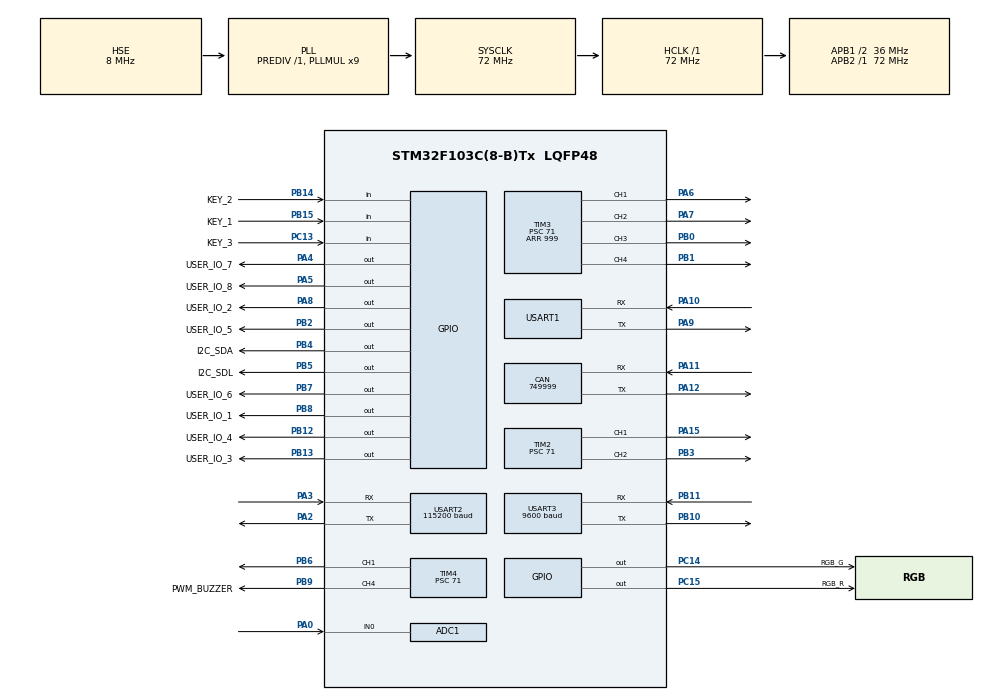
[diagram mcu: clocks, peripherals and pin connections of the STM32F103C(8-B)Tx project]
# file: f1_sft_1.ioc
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ADC1.Channel-4\#ChannelRegularConversion=ADC_CHANNEL_0
ADC1.NbrOfConversionFlag=1
ADC1.Rank-4\#ChannelRegularConversion=1
ADC1.SamplingTime-4\#ChannelRegularConversion=ADC_SAMPLETIME_1CYCLE_5
ADC1.master=1
CAN.CalculateBaudRate=749999
CAN.CalculateTimeBit=1333
CAN.CalculateTimeQuantum=444.44444444444446
Dma.Request0=USART1_RX
Dma.Request1=USART2_RX
Dma.Request2=USART1_TX
Dma.Request3=USART2_TX
Dma.USART1_RX.0.Direction=DMA_PERIPH_TO_MEMORY
Dma.USART1_RX.0.Instance=DMA1_Channel5
Dma.USART1_RX.0.MemDataAlignment=DMA_MDATAALIGN_BYTE
Dma.USART1_RX.0.MemInc=DMA_MINC_ENABLE
Dma.USART1_RX.0.Mode=DMA_CIRCULAR
Dma.USART1_RX.0.PeriphDataAlignment=DMA_PDATAALIGN_BYTE
Dma.USART1_RX.0.PeriphInc=DMA_PINC_DISABLE
Dma.USART1_RX.0.Priority=DMA_PRIORITY_LOW
Dma.USART1_TX.2.Direction=DMA_MEMORY_TO_PERIPH
Dma.USART1_TX.2.Instance=DMA1_Channel4
Dma.USART1_TX.2.MemDataAlignment=DMA_MDATAALIGN_BYTE
Dma.USART1_TX.2.MemInc=DMA_MINC_ENABLE
Dma.USART1_TX.2.Mode=DMA_NORMAL
Dma.USART1_TX.2.PeriphDataAlignment=DMA_PDATAALIGN_BYTE
Dma.USART1_TX.2.PeriphInc=DMA_PINC_DISABLE
Dma.USART1_TX.2.Priority=DMA_PRIORITY_LOW
Dma.USART2_RX.1.Direction=DMA_PERIPH_TO_MEMORY
Dma.USART2_RX.1.Instance=DMA1_Channel6
Dma.USART2_RX.1.MemDataAlignment=DMA_MDATAALIGN_BYTE
Dma.USART2_RX.1.MemInc=DMA_MINC_ENABLE
Dma.USART2_RX.1.Mode=DMA_CIRCULAR
Dma.USART2_RX.1.PeriphDataAlignment=DMA_PDATAALIGN_BYTE
Dma.USART2_RX.1.PeriphInc=DMA_PINC_DISABLE
Dma.USART2_RX.1.Priority=DMA_PRIORITY_LOW
Dma.USART2_TX.3.Direction=DMA_MEMORY_TO_PERIPH
Dma.USART2_TX.3.Instance=DMA1_Channel7
Dma.USART2_TX.3.MemDataAlignment=DMA_MDATAALIGN_BYTE
Dma.USART2_TX.3.MemInc=DMA_MINC_ENABLE
Dma.USART2_TX.3.Mode=DMA_NORMAL
Dma.USART2_TX.3.PeriphDataAlignment=DMA_PDATAALIGN_BYTE
Dma.USART2_TX.3.PeriphInc=DMA_PINC_DISABLE
Dma.USART2_TX.3.Priority=DMA_PRIORITY_LOW
FREERTOS.Tasks01=defaultTask,24,512,systemTaskUpdata,As weak,NULL,Dynamic,NULL,NULL;userTask_1,24,512,user1TaskUpdata,As weak,NULL,Dynamic,NULL,NULL;userTask_2,24,512,user2TaskUpdata,As weak,NULL,Dynamic,NULL,NULL
FREERTOS.configTOTAL_HEAP_SIZE=10240
Mcu.Family=STM32F1
Mcu.Name=STM32F103C(8-B)Tx
Mcu.Package=LQFP48
NVIC.DMA1_Channel4_IRQn=true\:5\:0\:false\:false\:true\:true\:false\:true\:true
NVIC.DMA1_Channel5_IRQn=true\:5\:0\:false\:false\:true\:true\:false\:true\:true
NVIC.DMA1_Channel6_IRQn=true\:5\:0\:false\:false\:true\:true\:false\:true\:true
NVIC.DMA1_Channel7_IRQn=true\:5\:0\:false\:false\:true\:true\:false\:true\:true
NVIC.PriorityGroup=NVIC_PRIORITYGROUP_4
NVIC.TIM1_UP_IRQn=true\:15\:0\:false\:false\:true\:false\:false\:true\:true
NVIC.TimeBase=TIM1_UP_IRQn
NVIC.TimeBaseIP=TIM1
NVIC.USART1_IRQn=true\:5\:0\:false\:false\:true\:true\:true\:true\:true
NVIC.USART2_IRQn=true\:5\:0\:false\:false\:true\:true\:true\:true\:true
NVIC.USART3_IRQn=true\:5\:0\:false\:false\:true\:true\:true\:true\:true
PA0-WKUP.Signal=ADCx_IN0
PA10.Mode=Asynchronous
PA10.Signal=USART1_RX
PA11.Mode=CAN_Activate
PA11.Signal=CAN_RX
PA12.Mode=CAN_Activate
PA12.Signal=CAN_TX
PA13.Mode=Serial_Wire
PA13.Signal=SYS_JTMS-SWDIO
PA14.Mode=Serial_Wire
PA14.Signal=SYS_JTCK-SWCLK
PA15.Signal=S_TIM2_CH1_ETR
PA2.Mode=Asynchronous
PA2.Signal=USART2_TX
PA3.Mode=Asynchronous
PA3.Signal=USART2_RX
PA4.GPIO_Label=USER_IO_7
PA4.GPIO_PuPd=GPIO_PULLUP
PA4.Signal=GPIO_Output
PA5.GPIO_Label=USER_IO_8
PA5.GPIO_PuPd=GPIO_PULLUP
PA5.Signal=GPIO_Output
PA6.Signal=S_TIM3_CH1
PA7.Signal=S_TIM3_CH2
PA8.GPIO_Label=USER_IO_2
PA8.GPIO_PuPd=GPIO_PULLUP
PA8.Signal=GPIO_Output
PA9.Mode=Asynchronous
PA9.Signal=USART1_TX
PB0.Signal=S_TIM3_CH3
PB1.Signal=S_TIM3_CH4
PB10.Mode=Asynchronous
PB10.Signal=USART3_TX
PB11.Mode=Asynchronous
PB11.Signal=USART3_RX
PB12.GPIO_Label=USER_IO_4
PB12.GPIO_PuPd=GPIO_PULLUP
PB12.Signal=GPIO_Output
PB13.GPIO_Label=USER_IO_3
PB13.GPIO_PuPd=GPIO_PULLUP
PB13.Signal=GPIO_Output
PB14.GPIO_Label=KEY_2
PB14.GPIO_PuPd=GPIO_PULLUP
PB14.Signal=GPIO_Input
PB15.GPIO_Label=KEY_1
PB15.GPIO_PuPd=GPIO_PULLUP
PB15.Signal=GPIO_Input
PB2.GPIO_Label=USER_IO_5
PB2.GPIO_PuPd=GPIO_PULLUP
PB2.Signal=GPIO_Output
PB3.Signal=S_TIM2_CH2
PB4.GPIO_Label=I2C_SDA
PB4.GPIO_ModeDefaultOutputPP=GPIO_MODE_OUTPUT_OD
PB4.GPIO_PuPd=GPIO_PULLUP
PB4.Signal=GPIO_Output
PB5.GPIO_Label=I2C_SDL
PB5.GPIO_PuPd=GPIO_PULLUP
PB5.Signal=GPIO_Output
PB6.Signal=S_TIM4_CH1
PB7.GPIO_Label=USER_IO_6
PB7.GPIO_PuPd=GPIO_PULLUP
PB7.Signal=GPIO_Output
PB8.GPIO_Label=USER_IO_1
PB8.GPIO_PuPd=GPIO_PULLUP
PB8.Signal=GPIO_Output
PB9.GPIO_Label=PWM_BUZZER
PB9.Signal=S_TIM4_CH4
PC13-TAMPER-RTC.GPIO_Label=KEY_3
PC13-TAMPER-RTC.GPIO_PuPd=GPIO_PULLUP
PC13-TAMPER-RTC.Signal=GPIO_Input
PC14-OSC32_IN.GPIO_Label=RGB_G
PC14-OSC32_IN.GPIO_PuPd=GPIO_PULLDOWN
PC14-OSC32_IN.Signal=GPIO_Output
PC15-OSC32_OUT.GPIO_Label=RGB_R
PC15-OSC32_OUT.GPIO_PuPd=GPIO_PULLDOWN
PC15-OSC32_OUT.Signal=GPIO_Output
PD0-OSC_IN.Mode=HSE-External-Oscillator
PD0-OSC_IN.Signal=RCC_OSC_IN
PD1-OSC_OUT.Mode=HSE-External-Oscillator
PD1-OSC_OUT.Signal=RCC_OSC_OUT
ProjectManager.HeapSize=0x200
ProjectManager.StackSize=0x400
ProjectManager.TargetToolchain=MDK-ARM V5
RCC.ADCPresc=RCC_ADCPCLK2_DIV6
RCC.AHBFreq_Value=72000000
RCC.APB1CLKDivider=RCC_HCLK_DIV2
RCC.APB1Freq_Value=36000000
RCC.APB1TimFreq_Value=72000000
RCC.APB2Freq_Value=72000000
RCC.APB2TimFreq_Value=72000000
RCC.HCLKFreq_Value=72000000
RCC.PLLMUL=RCC_PLL_MUL9
RCC.PLLSourceVirtual=RCC_PLLSOURCE_HSE
RCC.SYSCLKFreq_VALUE=72000000
RCC.SYSCLKSource=RCC_SYSCLKSOURCE_PLLCLK
RCC.USBFreq_Value=72000000
SH.ADCx_IN0.0=ADC1_IN0,IN0
SH.S_TIM2_CH1_ETR.0=TIM2_CH1,PWM Generation1 CH1
SH.S_TIM2_CH2.0=TIM2_CH2,PWM Generation2 CH2
SH.S_TIM3_CH1.0=TIM3_CH1,PWM Generation1 CH1
SH.S_TIM3_CH2.0=TIM3_CH2,PWM Generation2 CH2
SH.S_TIM3_CH3.0=TIM3_CH3,PWM Generation3 CH3
SH.S_TIM3_CH4.0=TIM3_CH4,PWM Generation4 CH4
SH.S_TIM4_CH1.0=TIM4_CH1,PWM Generation1 CH1
SH.S_TIM4_CH4.0=TIM4_CH4,PWM Generation4 CH4
TIM2.Channel-PWM\ Generation1\ CH1=TIM_CHANNEL_1
TIM2.Channel-PWM\ Generation2\ CH2=TIM_CHANNEL_2
TIM2.Period=19999
TIM2.Prescaler=71
TIM2.Pulse-PWM\ Generation1\ CH1=1000
TIM2.Pulse-PWM\ Generation2\ CH2=1000
TIM3.Channel-PWM\ Generation1\ CH1=TIM_CHANNEL_1
TIM3.Channel-PWM\ Generation2\ CH2=TIM_CHANNEL_2
TIM3.Channel-PWM\ Generation3\ CH3=TIM_CHANNEL_3
TIM3.Channel-PWM\ Generation4\ CH4=TIM_CHANNEL_4
TIM3.Period=999
TIM3.Prescaler=71
TIM3.Pulse-PWM\ Generation1\ CH1=500
TIM3.Pulse-PWM\ Generation2\ CH2=500
TIM3.Pulse-PWM\ Generation3\ CH3=500
TIM3.Pulse-PWM\ Generation4\ CH4=500
TIM4.Channel-PWM\ Generation1\ CH1=TIM_CHANNEL_1
TIM4.Channel-PWM\ Generation4\ CH4=TIM_CHANNEL_4
TIM4.Period=999
TIM4.Prescaler=71
TIM4.Pulse-PWM\ Generation1\ CH1=500
TIM4.Pulse-PWM\ Generation4\ CH4=500
USART1.VirtualMode=VM_ASYNC
USART2.BaudRate=115200
USART2.VirtualMode=VM_ASYNC
USART3.BaudRate=9600
USART3.VirtualMode=VM_ASYNC
VP_FREERTOS_VS_CMSIS_V2.Mode=CMSIS_V2
VP_SYS_VS_tim1.Mode=TIM1
VP_TIM2_VS_ClockSourceINT.Mode=Internal
VP_TIM3_VS_ClockSourceINT.Mode=Internal
VP_TIM4_VS_ClockSourceINT.Mode=Internal
board=custom

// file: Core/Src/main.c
/* USER CODE BEGIN Header */
/**
  ******************************************************************************
  * @file           : main.c
  * @brief          : Main program body
  ******************************************************************************
  * @attention
  *
  * Copyright (c) 2026 STMicroelectronics.
  * All rights reserved.
  *
  * This software is licensed under terms that can be found in the LICENSE file
  * in the root directory of this software component.
  * If no LICENSE file comes with this software, it is provided AS-IS.
  *
  ******************************************************************************
  */
/* USER CODE END Header */
#include "main.h"
#include "cmsis_os.h"
#include "adc.h"
#include "can.h"
#include "dma.h"
#include "tim.h"
#include "usart.h"
#include "gpio.h"

void SystemClock_Config(void);
void MX_FREERTOS_Init(void);

int main(void)
{

  /* MCU Configuration--------------------------------------------------------*/

  /* Reset of all peripherals, Initializes the Flash interface and the Systick. */
     HAL_Init();

  /* Configure the system clock */
  SystemClock_Config();

  /* Initialize all configured peripherals */
  MX_GPIO_Init();
  MX_DMA_Init();
  MX_TIM3_Init();
  MX_USART1_UART_Init();
  MX_USART2_UART_Init();
  MX_USART3_UART_Init();
  MX_TIM4_Init();
  MX_ADC1_Init();
  MX_CAN_Init();
  MX_TIM2_Init();

  /* Init scheduler */
  osKernelInitialize();  /* Call init function for freertos objects (in cmsis_os2.c) */
  MX_FREERTOS_Init();

  /* Start scheduler */
  osKernelStart();

  /* We should never get here as control is now taken by the scheduler */

  /* Infinite loop */
  while (1)
  {

  }
}

void SystemClock_Config(void)
{
  RCC_OscInitTypeDef RCC_OscInitStruct = {0};
  RCC_ClkInitTypeDef RCC_ClkInitStruct = {0};
  RCC_PeriphCLKInitTypeDef PeriphClkInit = {0};

  /** Initializes the RCC Oscillators according to the specified parameters
  * in the RCC_OscInitTypeDef structure.
  */
  RCC_OscInitStruct.OscillatorType = RCC_OSCILLATORTYPE_HSE;
  RCC_OscInitStruct.HSEState = RCC_HSE_ON;
  RCC_OscInitStruct.HSEPredivValue = RCC_HSE_PREDIV_DIV1;
  RCC_OscInitStruct.HSIState = RCC_HSI_ON;
  RCC_OscInitStruct.PLL.PLLState = RCC_PLL_ON;
  RCC_OscInitStruct.PLL.PLLSource = RCC_PLLSOURCE_HSE;
  RCC_OscInitStruct.PLL.PLLMUL = RCC_PLL_MUL9;
  if (HAL_RCC_OscConfig(&RCC_OscInitStruct) != HAL_OK)
  {
    Error_Handler();
  }

  /** Initializes the CPU, AHB and APB buses clocks
  */
  RCC_ClkInitStruct.ClockType = RCC_CLOCKTYPE_HCLK|RCC_CLOCKTYPE_SYSCLK
                              |RCC_CLOCKTYPE_PCLK1|RCC_CLOCKTYPE_PCLK2;
  RCC_ClkInitStruct.SYSCLKSource = RCC_SYSCLKSOURCE_PLLCLK;
  RCC_ClkInitStruct.AHBCLKDivider = RCC_SYSCLK_DIV1;
  RCC_ClkInitStruct.APB1CLKDivider = RCC_HCLK_DIV2;
  RCC_ClkInitStruct.APB2CLKDivider = RCC_HCLK_DIV1;

  if (HAL_RCC_ClockConfig(&RCC_ClkInitStruct, FLASH_LATENCY_2) != HAL_OK)
  {
    Error_Handler();
  }
  PeriphClkInit.PeriphClockSelection = RCC_PERIPHCLK_ADC;
  PeriphClkInit.AdcClockSelection = RCC_ADCPCLK2_DIV6;
  if (HAL_RCCEx_PeriphCLKConfig(&PeriphClkInit) != HAL_OK)
  {
    Error_Handler();
  }
}

void HAL_TIM_PeriodElapsedCallback(TIM_HandleTypeDef *htim)
{
  if (htim->Instance == TIM1)
  {
    HAL_IncTick();
  }
}

void Error_Handler(void)
{
  __disable_irq();
  while (1)
  {
  }
}

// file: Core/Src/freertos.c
/* USER CODE BEGIN Header */
/**
  ******************************************************************************
  * File Name          : freertos.c
  * Description        : Code for freertos applications
  ******************************************************************************
  * @attention
  *
  * Copyright (c) 2026 STMicroelectronics.
  * All rights reserved.
  *
  * This software is licensed under terms that can be found in the LICENSE file
  * in the root directory of this software component.
  * If no LICENSE file comes with this software, it is provided AS-IS.
  *
  ******************************************************************************
  */
/* USER CODE END Header */

#include "FreeRTOS.h"
#include "task.h"
#include "main.h"
#include "cmsis_os.h"

/* USER CODE BEGIN Includes */
#include "task_system.h"
#include "task_user1.h"

/* USER CODE END Includes */

/* Definitions for defaultTask */
osThreadId_t defaultTaskHandle;
const osThreadAttr_t defaultTask_attributes = {
  .name = "defaultTask",
  .stack_size = 512 * 4,
  .priority = (osPriority_t) osPriorityNormal,
};
/* Definitions for userTask_1 */
osThreadId_t userTask_1Handle;
const osThreadAttr_t userTask_1_attributes = {
  .name = "userTask_1",
  .stack_size = 512 * 4,
  .priority = (osPriority_t) osPriorityNormal,
};
/* Definitions for userTask_2 */
osThreadId_t userTask_2Handle;
const osThreadAttr_t userTask_2_attributes = {
  .name = "userTask_2",
  .stack_size = 512 * 4,
  .priority = (osPriority_t) osPriorityNormal,
};

void systemTaskUpdata(void *argument);
void user1TaskUpdata(void *argument);
void user2TaskUpdata(void *argument);

void MX_FREERTOS_Init(void); /* (MISRA C 2004 rule 8.1) */

void MX_FREERTOS_Init(void) {

  /* Create the thread(s) */
  /* creation of defaultTask */
  defaultTaskHandle = osThreadNew(systemTaskUpdata, NULL, &defaultTask_attributes);

  /* creation of userTask_1 */
  userTask_1Handle = osThreadNew(user1TaskUpdata, NULL, &userTask_1_attributes);

  /* creation of userTask_2 */
  userTask_2Handle = osThreadNew(user2TaskUpdata, NULL, &userTask_2_attributes);

}

__weak void systemTaskUpdata(void *argument)
{
  for(;;)
  {
    osDelay(1);
  }
}

__weak void user1TaskUpdata(void *argument)
{
  /* USER CODE BEGIN user1TaskUpdata */
  /* Infinite loop */
  for(;;)
  {
    osDelay(2);
  }
  /* USER CODE END user1TaskUpdata */
}

__weak void user2TaskUpdata(void *argument)
{
  /* USER CODE BEGIN user2TaskUpdata */
  /* Infinite loop */
  for(;;)
  {
    osDelay(2);
  }
  /* USER CODE END user2TaskUpdata */
}
